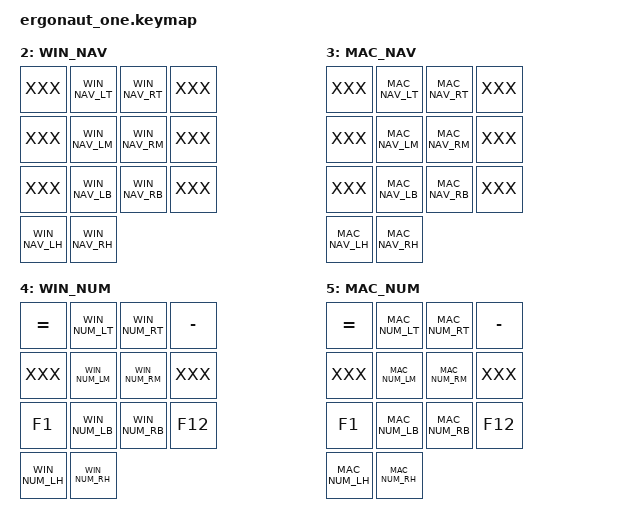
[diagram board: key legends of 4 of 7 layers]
#define CONFIG_WIRELESS

#include "zmk-helpers/key-labels/42.h"
#include "base.keymap"

ZMK_CONDITIONAL_LAYER(sys_win, WIN_NAV WIN_NUM, SYS)
ZMK_CONDITIONAL_LAYER(sys_mac, MAC_NAV MAC_NUM, SYS)

ZMK_LAYER(WIN_DEF,
    &kp EQUAL       WIN_DEF_LT  WIN_DEF_RT    &kp MINUS
    &kp LBKT        WIN_DEF_LM  WIN_DEF_RM    &kp RBKT
    &pipe_morph     WIN_DEF_LB  WIN_DEF_RB    &quote_morph
    WIN_DEF_LH          WIN_DEF_RH
)

ZMK_LAYER(MAC_DEF,
    &kp EQUAL       MAC_DEF_LT  MAC_DEF_RT    &kp MINUS
    &kp LBKT        MAC_DEF_LM  MAC_DEF_RM    &kp RBKT
    &pipe_morph     MAC_DEF_LB  MAC_DEF_RB    &quote_morph
    MAC_DEF_LH     MAC_DEF_RH
)

ZMK_LAYER(WIN_NAV,
    XXX     WIN_NAV_LT  WIN_NAV_RT    XXX
    XXX     WIN_NAV_LM  WIN_NAV_RM    XXX
    XXX     WIN_NAV_LB  WIN_NAV_RB    XXX
    WIN_NAV_LH  WIN_NAV_RH
)

ZMK_LAYER(MAC_NAV,
    XXX     MAC_NAV_LT  MAC_NAV_RT    XXX
    XXX     MAC_NAV_LM  MAC_NAV_RM    XXX
    XXX     MAC_NAV_LB  MAC_NAV_RB    XXX
    MAC_NAV_LH  MAC_NAV_RH
)

ZMK_LAYER(WIN_NUM,
    &kp EQUAL   WIN_NUM_LT  WIN_NUM_RT    &kp MINUS
    XXX         WIN_NUM_LM  WIN_NUM_RM    XXX
    &kp F1      WIN_NUM_LB  WIN_NUM_RB    &kp F12
    WIN_NUM_LH  WIN_NUM_RH
)

ZMK_LAYER(MAC_NUM,
    &kp EQUAL   MAC_NUM_LT  MAC_NUM_RT    &kp MINUS
    XXX         MAC_NUM_LM  MAC_NUM_RM    XXX
    &kp F1      MAC_NUM_LB  MAC_NUM_RB    &kp F12
    MAC_NUM_LH  MAC_NUM_RH
)

ZMK_LAYER(SYS,
    &bootloader     &studio_unlock  XXX XXX XXX XXX XXX XXX XXX XXX &studio_unlock  &bootloader
    &none           SYS_LM  SYS_RM  &none
    &sys_reset      XXX     XXX     XXX XXX &tog MAC_DEF  &tog MAC_DEF  XXX XXX XXX XXX &sys_reset
    SYS_LH          SYS_RH
)
